# netx90_app register map
File version: 1.0
CPU: CM4 r0p1, little endian, MPU, FPU, 4 interrupt priority bits, 78 interrupts
Registers are 32-bit, read-write, reset 0x0 unless marked. A register's access mark holds for its fields unless they carry their own. Offsets are from the block's base; [hi:lo] are bit positions.

## uart_app
Base 0xFF801040
Same registers: uart_xpic_app 0xFF900300
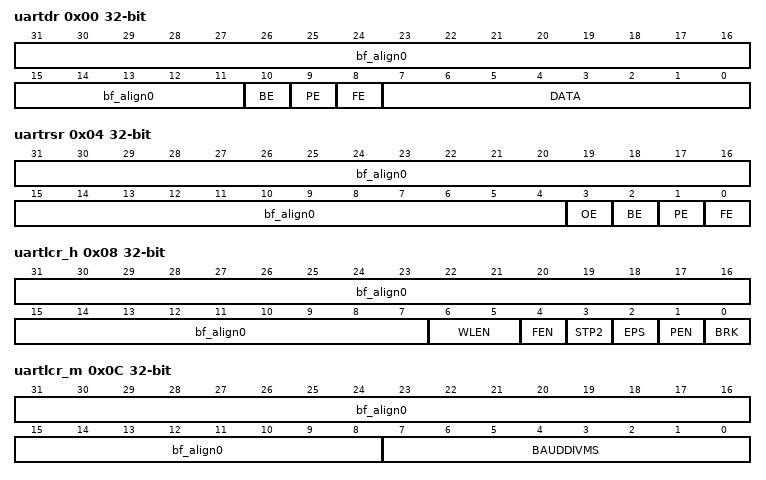
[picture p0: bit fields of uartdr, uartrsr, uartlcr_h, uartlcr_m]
0x00 uartdr (reset mask 0x7FF) — data read or written from the interface
  [31:11] bf_align0 — bitField alignment value for aeabi compatibility
  [10] BE — Break Error, read only, mirrored from uartrsr, to handle in DMA-read-out data
  [9] PE — Parity Error, read only, mirrored from uartrsr, to handle in DMA-read-out data
  [8] FE — Framing Error, read only, mirrored from uartrsr, to handle in DMA-read-out data
  [7:0] DATA — data read or written from the interface
0x04 uartrsr (reset mask 0xF) — receive status register (read) / Error Clear Register (write)
  [31:4] bf_align0 — bitField alignment value for aeabi compatibility
  [3] OE — Overrun Error
  [2] BE — Break Error
  [1] PE — Parity Error
  [0] FE — Framing Error
0x08 uartlcr_h (reset mask 0x7F) — Line control Register, high byte
  [31:7] bf_align0 — bitField alignment value for aeabi compatibility
  [6:5] WLEN — Word Length '00' 5 bits '01' 6 bits '10' 7 bits '11' 8 bits
  [4] FEN — FIFO Enable
  [3] STP2 — 2 Stop Bits Select
  [2] EPS — Even Parity Select
  [1] PEN — Parity Enalble
  [0] BRK — Send Break
0x0C uartlcr_m (reset mask 0xFF) — Line control Register, middle byte
  [31:8] bf_align0 — bitField alignment value for aeabi compatibility
  [7:0] BAUDDIVMS — bauddiv : Baud Divisor Most Significant Byte use higher byte of bauddiv = (system clk / (16 * baud rate)) - 1 if not alternative settings by register uartcr_2 are done
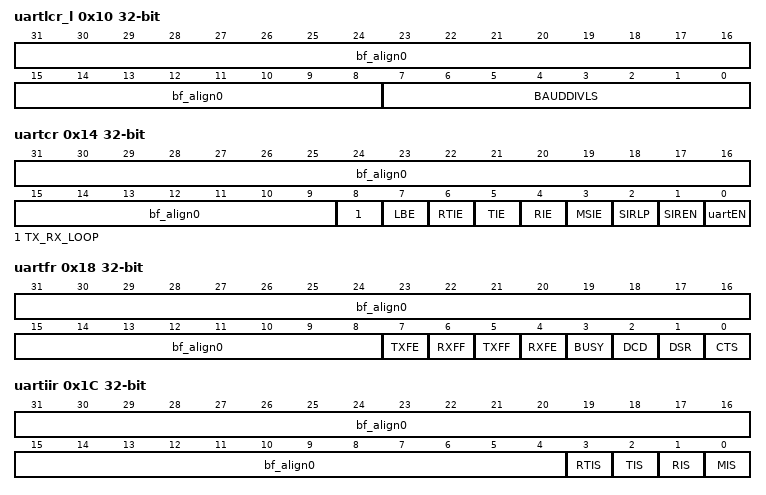
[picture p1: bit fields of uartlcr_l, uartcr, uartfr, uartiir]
0x10 uartlcr_l (reset mask 0xFF) — Line control Register, low byte
  [31:8] bf_align0 — bitField alignment value for aeabi compatibility
  [7:0] BAUDDIVLS — Baud Divisor Least Significant Byte use lower byte of bauddiv = (system clk / (16 * baud rate)) - 1 if not alternative settings by register uartcr_2 are done
0x14 uartcr (reset mask 0x1FF) — uart control Register
  [31:9] bf_align0 — bitField alignment value for aeabi compatibility
  [8] TX_RX_LOOP — internal loop (TX -> RX) (test purpose only)
  [7] LBE — Loop Back Enable for IrDA mode
  [6] RTIE — Receive Timeout Interrupt Enable
  [5] TIE — Transmit Interrupt Enable
  [4] RIE — Receive Interrupt Enable
  [3] MSIE — Modem Status Interrupt Enable
  [2] SIRLP — IrDA SIR Low Power Mode
  [1] SIREN — SIR Enable
  [0] uartEN — uart Enable
0x18 uartfr ro (reset mask 0xFF) — uart Flag Register
  [31:8] bf_align0 — bitField alignment value for aeabi compatibility
  [7] TXFE — Transmit FIFO Empty
  [6] RXFF — Receive FIFO Full
  [5] TXFF — Transmit FIFO Full
  [4] RXFE — Receive FIFO Empty
  [3] BUSY — uart BUSY
  [2] DCD — Data Carrier Detect
  [1] DSR — Data Set Ready
  [0] CTS — Clear To Send
0x1C uartiir (reset mask 0xF) — Interrupt Identification (read) / interrupt clear (write)
  [31:4] bf_align0 — bitField alignment value for aeabi compatibility
  [3] RTIS — Receive Timeout Interrupt Status
  [2] TIS — Transmit Interrupt Status
  [1] RIS — Receive Interrupt Status
  [0] MIS — Modem Interrupt Status
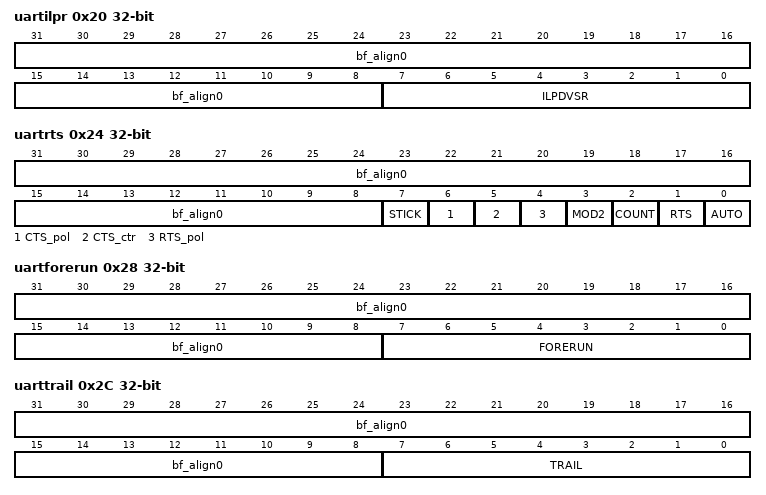
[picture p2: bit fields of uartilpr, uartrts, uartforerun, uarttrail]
0x20 uartilpr (reset mask 0xFF) — IrDA Low Power Counter Register
  [31:8] bf_align0 — bitField alignment value for aeabi compatibility
  [7:0] ILPDVSR — IrDA Low Power Divisor
0x24 uartrts (reset mask 0xFF) — RTS Control Register
  [31:8] bf_align0 — bitField alignment value for aeabi compatibility
  [7] STICK — stick parity
  [6] CTS_pol — nUARTCTS polarity: 1=active high
  [5] CTS_ctr — nUARTCTS control
  [4] RTS_pol — RTS polarity: 1=active high
  [3] MOD2 — mode1/mode2
  [2] COUNT — count base: 1=system clocks, 0=time in bauds
  [1] RTS — if AUTO=0: controlled by this bit
  [0] AUTO — automatic or controlled by the next bit (RTS)
0x28 uartforerun (reset mask 0xFF) — RTS forerun cycles
  [31:8] bf_align0 — bitField alignment value for aeabi compatibility
  [7:0] FORERUN — number of forerun cycles in system clocks or bauds
0x2C uarttrail (reset mask 0xFF) — RTS trail cycles
  [31:8] bf_align0 — bitField alignment value for aeabi compatibility
  [7:0] TRAIL — number of trail cycles in system clocks or bauds
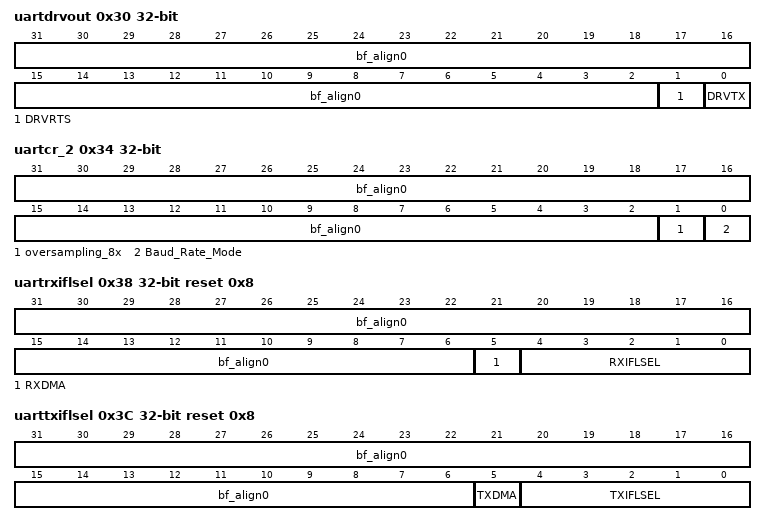
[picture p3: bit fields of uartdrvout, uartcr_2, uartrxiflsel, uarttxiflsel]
0x30 uartdrvout (reset mask 0x3) — Drive Output
  [31:2] bf_align0 — bitField alignment value for aeabi compatibility
  [1] DRVRTS — enable driver for RTS
  [0] DRVTX — enable driver for TX
0x34 uartcr_2 (reset mask 0x3) — Control Register 2
  [31:2] bf_align0 — bitField alignment value for aeabi compatibility
  [1] oversampling_8x — Oversampling mode: 0: Use default 16x oversampling. 1: Use reduced accuracy 8x oversampling. This can be used to increase the max. baudrate. When selected, the configured baudrate will be doubled. Note that the bit reception is more error-prone in noisy environments.
  [0] Baud_Rate_Mode — If this bit is set the baud rate is generated more exactly by the following formula: value = ( (Baud Rate * 16) / System Frequency ) * 2^16 . You have to write this 16-bit value in register uartlcr_l and uartlcr_m.
0x38 uartrxiflsel reset 0x8 (reset mask 0x3F) — RX FIFO trigger level and RX-DMA enable
  [31:6] bf_align0 — bitField alignment value for aeabi compatibility
  [5] RXDMA — Enable DMA-requests for RX-fifo-data. A request will be generated if RX-FIFO is not empty and uartcr.uartEN (module enable) is set. Burst request to DMA-Ctrl will be done if the RX-FIFO contains at least 4 words (set DMA-burst-size to 4) If this bit is reset or the module is disabled, DMA-request will also be reset. single transfer request: RX-FIFO contains 1 byte or more, burst request: 4 bytes or more note: set adr_dmac_chctrl.SBSize = 1 (i.e. burst size: 4) in the DMA module
  [4:0] RXIFLSEL — Choose a number between 1 and 16. It defines the IRQ trigger level of the receive fifo. The IRQ (UARTRXINTR) will be set if the number of received bytes in the receive fifo are greater than or equal RXIFLSEL.
0x3C uarttxiflsel reset 0x8 (reset mask 0x3F) — TX FIFO trigger level and TX-DMA enable
  [31:6] bf_align0 — bitField alignment value for aeabi compatibility
  [5] TXDMA — Enable DMA-requests for TX-fifo-data. A request will be generated if TX-FIFO is not full and uartcr.uartEN (module enable) is set. Burst request to DMA-Ctrl will be done if at least 4 words are writable to the TX-FIFO (set DMA-burst-size to 4) If this bit is reset or the module is disabled, DMA-request will also be reset. note: set adr_dmac_chctrl.DBSize = 1 (i.e. burst size: 4) in the DMA module
  [4:0] TXIFLSEL — Choose a number between 1 and 16. It defines the IRQ trigger level of the transmit fifo. The IRQ (UARTTXINTR) will be set if the number of transmitted bytes in the transmit fifo are less than TXIFLSEL.
